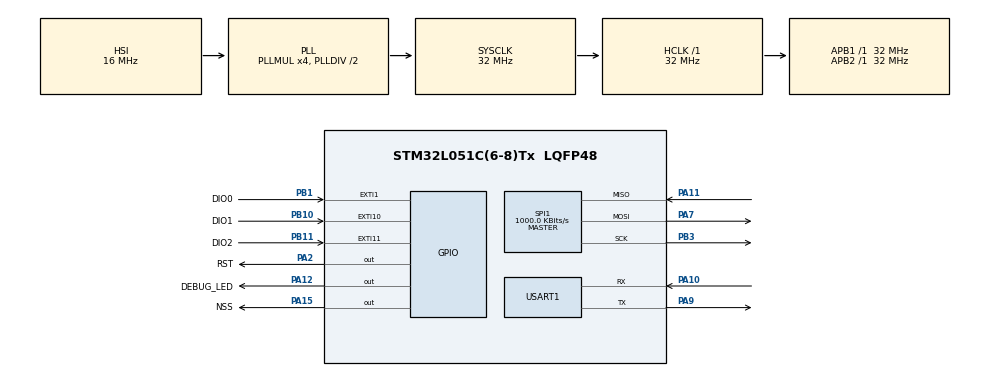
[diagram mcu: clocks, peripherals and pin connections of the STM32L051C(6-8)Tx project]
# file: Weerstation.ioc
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Mcu.Family=STM32L0
Mcu.Name=STM32L051C(6-8)Tx
Mcu.Package=LQFP48
NVIC.TIM2_IRQn=true\:0\:0\:false\:false\:true\:true\:true\:true
PA10.Mode=Asynchronous
PA10.Signal=USART1_RX
PA11.Mode=Full_Duplex_Master
PA11.Signal=SPI1_MISO
PA12.GPIO_Label=DEBUG_LED
PA12.Signal=GPIO_Output
PA13.Mode=Serial_Wire
PA13.Signal=SYS_SWDIO
PA14.Mode=Serial_Wire
PA14.Signal=SYS_SWCLK
PA15.GPIO_Label=NSS
PA15.Signal=GPIO_Output
PA2.GPIO_Label=RST
PA2.Signal=GPIO_Output
PA7.Mode=Full_Duplex_Master
PA7.Signal=SPI1_MOSI
PA9.Mode=Asynchronous
PA9.Signal=USART1_TX
PB1.GPIO_Label=DIO0
PB1.Signal=GPXTI1
PB10.GPIO_Label=DIO1
PB10.Signal=GPXTI10
PB11.GPIO_Label=DIO2
PB11.Signal=GPXTI11
PB3.Mode=Full_Duplex_Master
PB3.Signal=SPI1_SCK
ProjectManager.HeapSize=0x200
ProjectManager.StackSize=0x400
ProjectManager.TargetToolchain=STM32CubeIDE
RCC.AHBFreq_Value=32000000
RCC.APB1Freq_Value=32000000
RCC.APB1TimFreq_Value=32000000
RCC.APB2Freq_Value=32000000
RCC.APB2TimFreq_Value=32000000
RCC.HCLKFreq_Value=32000000
RCC.HSE_VALUE=8000000
RCC.HSI16_VALUE=16000000
RCC.HSI_VALUE=16000000
RCC.MSI_VALUE=2097000
RCC.PLLMUL=RCC_PLLMUL_4
RCC.SYSCLKFreq_VALUE=32000000
RCC.SYSCLKSource=RCC_SYSCLKSOURCE_PLLCLK
RCC.VCOOutputFreq_Value=64000000
SPI1.BaudRatePrescaler=SPI_BAUDRATEPRESCALER_32
SPI1.CalculateBaudRate=1000.0 KBits/s
SPI1.Direction=SPI_DIRECTION_2LINES
SPI1.Mode=SPI_MODE_MASTER
SPI1.VirtualType=VM_MASTER
TIM2.Channel-Output\ Compare1\ No\ Output=TIM_CHANNEL_1
TIM2.Period=65535-1
TIM2.Prescaler=2250-1
USART1.VirtualMode-Asynchronous=VM_ASYNC
VP_TIM2_VS_no_output1.Mode=Output Compare1 No Output
board=custom

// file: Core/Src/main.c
/* USER CODE BEGIN Header */
/**
  ******************************************************************************
  * @file           : main.c
  * @brief          : Main program body
  ******************************************************************************
  * @attention
  *
  * Copyright (c) 2022 STMicroelectronics.
  * All rights reserved.
  *
  * This software is licensed under terms that can be found in the LICENSE file
  * in the root directory of this software component.
  * If no LICENSE file comes with this software, it is provided AS-IS.
  *
  ******************************************************************************
  */
/* USER CODE END Header */
#include "main.h"

/* USER CODE BEGIN Includes */
#include "lmic.h"
#include "debug.h"
/* USER CODE END Includes */

 SPI_HandleTypeDef hspi1;

TIM_HandleTypeDef htim2;

UART_HandleTypeDef huart1;

void SystemClock_Config(void);
static void MX_GPIO_Init(void);
static void MX_SPI1_Init(void);
static void MX_TIM2_Init(void);
static void MX_USART1_UART_Init(void);

int main(void)
{

  /* MCU Configuration--------------------------------------------------------*/

  /* Reset of all peripherals, Initializes the Flash interface and the Systick. */
  HAL_Init();

  /* Configure the system clock */
  SystemClock_Config();

  /* Initialize all configured peripherals */
  MX_GPIO_Init();
  MX_SPI1_Init();
  MX_TIM2_Init();
  MX_USART1_UART_Init();

  /* Infinite loop */
  /* USER CODE BEGIN WHILE */
  while (1)
  {

	  HAL_GPIO_TogglePin (DEBUG_LED_GPIO_Port, DEBUG_LED_Pin);
	  HAL_Delay (1000);   /* Insert delay 100 ms */

    /* USER CODE END WHILE */

  }
}

void SystemClock_Config(void)
{
  RCC_OscInitTypeDef RCC_OscInitStruct = {0};
  RCC_ClkInitTypeDef RCC_ClkInitStruct = {0};
  RCC_PeriphCLKInitTypeDef PeriphClkInit = {0};

  /** Configure the main internal regulator output voltage
  */
  __HAL_PWR_VOLTAGESCALING_CONFIG(PWR_REGULATOR_VOLTAGE_SCALE1);

  /** Initializes the RCC Oscillators according to the specified parameters
  * in the RCC_OscInitTypeDef structure.
  */
  RCC_OscInitStruct.OscillatorType = RCC_OSCILLATORTYPE_HSI;
  RCC_OscInitStruct.HSIState = RCC_HSI_ON;
  RCC_OscInitStruct.HSICalibrationValue = RCC_HSICALIBRATION_DEFAULT;
  RCC_OscInitStruct.PLL.PLLState = RCC_PLL_ON;
  RCC_OscInitStruct.PLL.PLLSource = RCC_PLLSOURCE_HSI;
  RCC_OscInitStruct.PLL.PLLMUL = RCC_PLLMUL_4;
  RCC_OscInitStruct.PLL.PLLDIV = RCC_PLLDIV_2;
  if (HAL_RCC_OscConfig(&RCC_OscInitStruct) != HAL_OK)
  {
    Error_Handler();
  }

  /** Initializes the CPU, AHB and APB buses clocks
  */
  RCC_ClkInitStruct.ClockType = RCC_CLOCKTYPE_HCLK|RCC_CLOCKTYPE_SYSCLK
                              |RCC_CLOCKTYPE_PCLK1|RCC_CLOCKTYPE_PCLK2;
  RCC_ClkInitStruct.SYSCLKSource = RCC_SYSCLKSOURCE_PLLCLK;
  RCC_ClkInitStruct.AHBCLKDivider = RCC_SYSCLK_DIV1;
  RCC_ClkInitStruct.APB1CLKDivider = RCC_HCLK_DIV1;
  RCC_ClkInitStruct.APB2CLKDivider = RCC_HCLK_DIV1;

  if (HAL_RCC_ClockConfig(&RCC_ClkInitStruct, FLASH_LATENCY_1) != HAL_OK)
  {
    Error_Handler();
  }
  PeriphClkInit.PeriphClockSelection = RCC_PERIPHCLK_USART1;
  PeriphClkInit.Usart1ClockSelection = RCC_USART1CLKSOURCE_PCLK2;
  if (HAL_RCCEx_PeriphCLKConfig(&PeriphClkInit) != HAL_OK)
  {
    Error_Handler();
  }
}

static void MX_SPI1_Init(void)
{

  /* SPI1 parameter configuration*/
  hspi1.Instance = SPI1;
  hspi1.Init.Mode = SPI_MODE_MASTER;
  hspi1.Init.Direction = SPI_DIRECTION_2LINES;
  hspi1.Init.DataSize = SPI_DATASIZE_8BIT;
  hspi1.Init.CLKPolarity = SPI_POLARITY_LOW;
  hspi1.Init.CLKPhase = SPI_PHASE_1EDGE;
  hspi1.Init.NSS = SPI_NSS_SOFT;
  hspi1.Init.BaudRatePrescaler = SPI_BAUDRATEPRESCALER_32;
  hspi1.Init.FirstBit = SPI_FIRSTBIT_MSB;
  hspi1.Init.TIMode = SPI_TIMODE_DISABLE;
  hspi1.Init.CRCCalculation = SPI_CRCCALCULATION_DISABLE;
  hspi1.Init.CRCPolynomial = 7;
  if (HAL_SPI_Init(&hspi1) != HAL_OK)
  {
    Error_Handler();
  }

}

static void MX_TIM2_Init(void)
{

  TIM_MasterConfigTypeDef sMasterConfig = {0};
  TIM_OC_InitTypeDef sConfigOC = {0};

  htim2.Instance = TIM2;
  htim2.Init.Prescaler = 2250-1;
  htim2.Init.CounterMode = TIM_COUNTERMODE_UP;
  htim2.Init.Period = 65535-1;
  htim2.Init.ClockDivision = TIM_CLOCKDIVISION_DIV1;
  htim2.Init.AutoReloadPreload = TIM_AUTORELOAD_PRELOAD_DISABLE;
  if (HAL_TIM_OC_Init(&htim2) != HAL_OK)
  {
    Error_Handler();
  }
  sMasterConfig.MasterOutputTrigger = TIM_TRGO_RESET;
  sMasterConfig.MasterSlaveMode = TIM_MASTERSLAVEMODE_DISABLE;
  if (HAL_TIMEx_MasterConfigSynchronization(&htim2, &sMasterConfig) != HAL_OK)
  {
    Error_Handler();
  }
  sConfigOC.OCMode = TIM_OCMODE_TIMING;
  sConfigOC.Pulse = 0;
  sConfigOC.OCPolarity = TIM_OCPOLARITY_HIGH;
  sConfigOC.OCFastMode = TIM_OCFAST_DISABLE;
  if (HAL_TIM_OC_ConfigChannel(&htim2, &sConfigOC, TIM_CHANNEL_1) != HAL_OK)
  {
    Error_Handler();
  }

}

static void MX_USART1_UART_Init(void)
{

  huart1.Instance = USART1;
  huart1.Init.BaudRate = 115200;
  huart1.Init.WordLength = UART_WORDLENGTH_8B;
  huart1.Init.StopBits = UART_STOPBITS_1;
  huart1.Init.Parity = UART_PARITY_NONE;
  huart1.Init.Mode = UART_MODE_TX_RX;
  huart1.Init.HwFlowCtl = UART_HWCONTROL_NONE;
  huart1.Init.OverSampling = UART_OVERSAMPLING_16;
  huart1.Init.OneBitSampling = UART_ONE_BIT_SAMPLE_DISABLE;
  huart1.AdvancedInit.AdvFeatureInit = UART_ADVFEATURE_NO_INIT;
  if (HAL_UART_Init(&huart1) != HAL_OK)
  {
    Error_Handler();
  }

}

static void MX_GPIO_Init(void)
{
  GPIO_InitTypeDef GPIO_InitStruct = {0};

  /* GPIO Ports Clock Enable */
  __HAL_RCC_GPIOA_CLK_ENABLE();
  __HAL_RCC_GPIOB_CLK_ENABLE();

  /*Configure GPIO pin Output Level */
  HAL_GPIO_WritePin(GPIOA, RST_Pin|DEBUG_LED_Pin|NSS_Pin, GPIO_PIN_RESET);

  /*Configure GPIO pins : RST_Pin DEBUG_LED_Pin NSS_Pin */
  GPIO_InitStruct.Pin = RST_Pin|DEBUG_LED_Pin|NSS_Pin;
  GPIO_InitStruct.Mode = GPIO_MODE_OUTPUT_PP;
  GPIO_InitStruct.Pull = GPIO_NOPULL;
  GPIO_InitStruct.Speed = GPIO_SPEED_FREQ_LOW;
  HAL_GPIO_Init(GPIOA, &GPIO_InitStruct);

  /*Configure GPIO pins : DIO0_Pin DIO1_Pin DIO2_Pin */
  GPIO_InitStruct.Pin = DIO0_Pin|DIO1_Pin|DIO2_Pin;
  GPIO_InitStruct.Mode = GPIO_MODE_IT_RISING;
  GPIO_InitStruct.Pull = GPIO_NOPULL;
  HAL_GPIO_Init(GPIOB, &GPIO_InitStruct);

}

void Error_Handler(void)
{
  __disable_irq();
  while (1)
  {
  }
}
